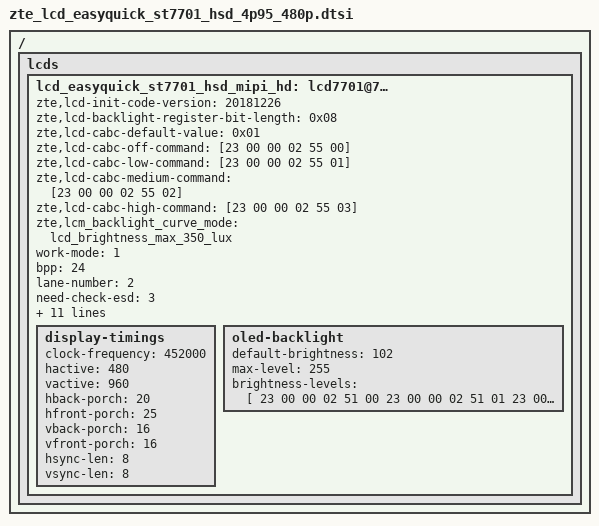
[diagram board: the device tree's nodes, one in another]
/ { lcds {
	lcd_easyquick_st7701_hsd_mipi_hd: lcd7701@7701 {
		zte,lcd-init-code-version = "20181226";
		zte,lcd-backlight-register-bit-length = <0x08>;
		zte,lcd-cabc-default-value = <0x01>;
		zte,lcd-cabc-off-command = [23 00 00 02 55 00];
		zte,lcd-cabc-low-command = [23 00 00 02 55 01];
		zte,lcd-cabc-medium-command = [23 00 00 02 55 02];
		zte,lcd-cabc-high-command = [23 00 00 02 55 03];
		zte,lcm_backlight_curve_mode = "lcd_brightness_max_350_lux";

		work-mode = <1>;
		bpp = <24>;
		lane-number = <2>;

		need-check-esd = <3>;
		esd-timeout = <2000>;

		fps = <60>;
		width-mm = <56>;
		height-mm = <112>;
		panel-name = "lcd_easyquick_st7701_hsd_mipi_hd";

		power-on-sequence = <
					50  1  5
					50  0  5
					50  1  120
					>;
		power-off-sequence = <
					50  0  120
					>;

		init-data = [
			39 00 00 06 FF 77 01 00 00 13
			39 00 00 02 EF 08
			39 00 00 03 E8 00 0E
			39 0a 00 03 E8 00 0C
			39 00 00 03 E8 00 00
			39 00 00 06 FF 77 01 00 00 10
			39 00 00 03 C0 77 00
			39 00 00 03 C1 0E 02
			39 00 00 03 C2 07 02
			39 00 00 02 CC 38
			39 00 00 02 BB 00
			39 00 00 02 CA 11
			39 00 00 02 BC 01
			39 00 00 11 B0 00 03 0B 0E 16 0C 0C 09 09 1F 09 15 11 8F 12 D4
			39 00 00 11 B1 00 03 09 10 16 09 08 0A 09 22 08 16 13 96 22 D4
			39 00 00 06 FF 77 01 00 00 11
			39 00 00 02 B0 47
			39 00 00 02 B1 5B
			39 00 00 02 B2 87
			39 00 00 02 B3 80
			39 00 00 02 B5 4E
			39 00 00 02 B7 87
			39 00 00 02 B8 20
			39 00 00 02 BB 03
			39 00 00 02 C1 78
			39 00 00 02 C2 78
			39 64 00 02 D0 88
			39 00 00 04 E0 00 00 02
			39 00 00 0C E1 07 8C 09 8C 06 8C 08 8C 00 44 44
			39 00 00 0E E2 00 00 00 00 00 00 00 00 00 00 00 00 00
			39 00 00 05 E3 00 00 33 33
			39 00 00 03 E4 44 44
			39 00 00 11 E5 0F CA 8C 8C 11 CA 8C 8C 0B CA 8C 8C 0D CA 8C 8C
			39 00 00 05 E6 00 00 33 33
			39 00 00 03 E7 44 44
			39 00 00 11 E8 0E CA 8C 8C 10 CA 8C 8C 0A CA 8C 8C 0C CA 8C 8C
			39 00 00 08 EB 02 00 00 00 00 00 00
			39 00 00 11 ED AB 89 76 54 01 FF FF FF FF FF FF 10 45 67 98 BA
			39 00 00 06 FF 77 01 00 00 00
			39 00 00 02 35 00
			39 00 00 02 51 00
			39 00 00 02 53 2C
			39 00 00 02 55 01
			23 78 00 02 11 00
			23 0a 00 02 29 00
			];
		sleep-in = [
			13 0A 00 01 28
			13 78 00 01 10
			];
		sleep-out = [
			13 78 00 01 11
			13 64 00 01 29
			];

		display-timings {
			clock-frequency = <452000>;
			hactive = <480>;
			vactive = <960>;
			hback-porch = <20>;
			hfront-porch = <25>;
			vback-porch = <16>;
			vfront-porch = <16>;
			hsync-len = <8>;
			vsync-len = <8>;
		};
		oled-backlight {
			default-brightness = <102>;
			max-level = <255>;
			brightness-levels = [
				23 00 00 02 51 00
				23 00 00 02 51 01
				23 00 00 02 51 02
				23 00 00 02 51 03
				23 00 00 02 51 04
				23 00 00 02 51 05
				23 00 00 02 51 06
				23 00 00 02 51 07
				23 00 00 02 51 08
				23 00 00 02 51 09
				23 00 00 02 51 0A
				23 00 00 02 51 0A
				23 00 00 02 51 0B
				23 00 00 02 51 0B
				23 00 00 02 51 0C
				23 00 00 02 51 0C
				23 00 00 02 51 0D
				23 00 00 02 51 0D
				23 00 00 02 51 0E
				23 00 00 02 51 0E
				23 00 00 02 51 0F
				23 00 00 02 51 0F
				23 00 00 02 51 10
				23 00 00 02 51 11
				23 00 00 02 51 11
				23 00 00 02 51 12
				23 00 00 02 51 12
				23 00 00 02 51 13
				23 00 00 02 51 13
				23 00 00 02 51 14
				23 00 00 02 51 14
				23 00 00 02 51 15
				23 00 00 02 51 15
				23 00 00 02 51 16
				23 00 00 02 51 17
				23 00 00 02 51 17
				23 00 00 02 51 18
				23 00 00 02 51 18
				23 00 00 02 51 19
				23 00 00 02 51 19
				23 00 00 02 51 1A
				23 00 00 02 51 1A
				23 00 00 02 51 1B
				23 00 00 02 51 1B
				23 00 00 02 51 1C
				23 00 00 02 51 1D
				23 00 00 02 51 1D
				23 00 00 02 51 1E
				23 00 00 02 51 1E
				23 00 00 02 51 1F
				23 00 00 02 51 1F
				23 00 00 02 51 20
				23 00 00 02 51 20
				23 00 00 02 51 21
				23 00 00 02 51 21
				23 00 00 02 51 22
				23 00 00 02 51 23
				23 00 00 02 51 23
				23 00 00 02 51 24
				23 00 00 02 51 24
				23 00 00 02 51 25
				23 00 00 02 51 25
				23 00 00 02 51 26
				23 00 00 02 51 26
				23 00 00 02 51 27
				23 00 00 02 51 27
				23 00 00 02 51 28
				23 00 00 02 51 28
				23 00 00 02 51 29
				23 00 00 02 51 2A
				23 00 00 02 51 2A
				23 00 00 02 51 2B
				23 00 00 02 51 2B
				23 00 00 02 51 2C
				23 00 00 02 51 2C
				23 00 00 02 51 2D
				23 00 00 02 51 2D
				23 00 00 02 51 2E
				23 00 00 02 51 2E
				23 00 00 02 51 2F
				23 00 00 02 51 30
				23 00 00 02 51 30
				23 00 00 02 51 31
				23 00 00 02 51 31
				23 00 00 02 51 32
				23 00 00 02 51 32
				23 00 00 02 51 33
				23 00 00 02 51 33
				23 00 00 02 51 34
				23 00 00 02 51 34
				23 00 00 02 51 35
				23 00 00 02 51 36
				23 00 00 02 51 36
				23 00 00 02 51 37
				23 00 00 02 51 37
				23 00 00 02 51 38
				23 00 00 02 51 38
				23 00 00 02 51 39
				23 00 00 02 51 39
				23 00 00 02 51 3A
				23 00 00 02 51 3A
				23 00 00 02 51 3B
				23 00 00 02 51 3C
				23 00 00 02 51 3C
				23 00 00 02 51 3C
				23 00 00 02 51 3D
				23 00 00 02 51 3D
				23 00 00 02 51 3D
				23 00 00 02 51 3E
				23 00 00 02 51 3E
				23 00 00 02 51 3F
				23 00 00 02 51 3F
				23 00 00 02 51 3F
				23 00 00 02 51 40
				23 00 00 02 51 40
				23 00 00 02 51 41
				23 00 00 02 51 41
				23 00 00 02 51 41
				23 00 00 02 51 42
				23 00 00 02 51 42
				23 00 00 02 51 43
				23 00 00 02 51 43
				23 00 00 02 51 43
				23 00 00 02 51 44
				23 00 00 02 51 44
				23 00 00 02 51 45
				23 00 00 02 51 45
				23 00 00 02 51 46
				23 00 00 02 51 46
				23 00 00 02 51 47
				23 00 00 02 51 48
				23 00 00 02 51 49
				23 00 00 02 51 4A
				23 00 00 02 51 4B
				23 00 00 02 51 4C
				23 00 00 02 51 4C
				23 00 00 02 51 4D
				23 00 00 02 51 4E
				23 00 00 02 51 4F
				23 00 00 02 51 50
				23 00 00 02 51 51
				23 00 00 02 51 52
				23 00 00 02 51 52
				23 00 00 02 51 53
				23 00 00 02 51 54
				23 00 00 02 51 55
				23 00 00 02 51 56
				23 00 00 02 51 57
				23 00 00 02 51 58
				23 00 00 02 51 58
				23 00 00 02 51 59
				23 00 00 02 51 5A
				23 00 00 02 51 5B
				23 00 00 02 51 5C
				23 00 00 02 51 5D
				23 00 00 02 51 5E
				23 00 00 02 51 5E
				23 00 00 02 51 5F
				23 00 00 02 51 60
				23 00 00 02 51 61
				23 00 00 02 51 62
				23 00 00 02 51 63
				23 00 00 02 51 64
				23 00 00 02 51 64
				23 00 00 02 51 65
				23 00 00 02 51 66
				23 00 00 02 51 67
				23 00 00 02 51 68
				23 00 00 02 51 69
				23 00 00 02 51 6A
				23 00 00 02 51 6A
				23 00 00 02 51 6B
				23 00 00 02 51 6C
				23 00 00 02 51 6D
				23 00 00 02 51 6E
				23 00 00 02 51 6F
				23 00 00 02 51 70
				23 00 00 02 51 70
				23 00 00 02 51 71
				23 00 00 02 51 72
				23 00 00 02 51 73
				23 00 00 02 51 74
				23 00 00 02 51 75
				23 00 00 02 51 76
				23 00 00 02 51 76
				23 00 00 02 51 77
				23 00 00 02 51 78
				23 00 00 02 51 79
				23 00 00 02 51 7A
				23 00 00 02 51 7B
				23 00 00 02 51 7C
				23 00 00 02 51 7C
				23 00 00 02 51 7D
				23 00 00 02 51 7E
				23 00 00 02 51 7F
				23 00 00 02 51 80
				23 00 00 02 51 81
				23 00 00 02 51 82
				23 00 00 02 51 83
				23 00 00 02 51 83
				23 00 00 02 51 84
				23 00 00 02 51 85
				23 00 00 02 51 86
				23 00 00 02 51 87
				23 00 00 02 51 88
				23 00 00 02 51 89
				23 00 00 02 51 89
				23 00 00 02 51 8A
				23 00 00 02 51 8B
				23 00 00 02 51 8C
				23 00 00 02 51 8D
				23 00 00 02 51 8E
				23 00 00 02 51 8F
				23 00 00 02 51 8F
				23 00 00 02 51 90
				23 00 00 02 51 91
				23 00 00 02 51 92
				23 00 00 02 51 93
				23 00 00 02 51 94
				23 00 00 02 51 95
				23 00 00 02 51 95
				23 00 00 02 51 96
				23 00 00 02 51 97
				23 00 00 02 51 98
				23 00 00 02 51 99
				23 00 00 02 51 9A
				23 00 00 02 51 9B
				23 00 00 02 51 9B
				23 00 00 02 51 9C
				23 00 00 02 51 9D
				23 00 00 02 51 9E
				23 00 00 02 51 9F
				23 00 00 02 51 A0
				23 00 00 02 51 A1
				23 00 00 02 51 A1
				23 00 00 02 51 A2
				23 00 00 02 51 A3
				23 00 00 02 51 A4
				23 00 00 02 51 A5
				23 00 00 02 51 A6
				23 00 00 02 51 A7
				23 00 00 02 51 A7
				23 00 00 02 51 A8
				23 00 00 02 51 A9
				23 00 00 02 51 AA
				23 00 00 02 51 AB
				23 00 00 02 51 AC
				23 00 00 02 51 AD
				23 00 00 02 51 B0
				23 00 00 02 51 BF
				23 00 00 02 51 C0
				23 00 00 02 51 CF
				23 00 00 02 51 D0
				23 00 00 02 51 DF
				23 00 00 02 51 F0
				23 00 00 02 51 FF
			];
		};
	};
};};

